# R7FA6T1 register map
Vendor: Renesas; Series: RA6; File version: 1.2
CPU: CM4 r0p1, little endian, MPU, FPU, VTOR, 4 interrupt priority bits
Registers are 8-bit, read-write, reset 0x0 unless marked. A register's access mark holds for its fields unless they carry their own. Offsets are from the block's base; [hi:lo] are bit positions; {n}, {i} and the like mark numbered series; 'fields as' and 'values as' point back to an identical list.

## GPT_OPS — Output Phase Switching Controller
Base 0x40078FF0
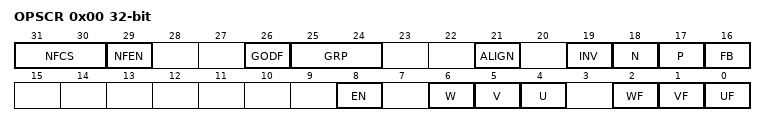
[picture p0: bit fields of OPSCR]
0x00 OPSCR 32-bit — Output Phase Switching Control Register
  [31:30] NFCS — External Input Noise Filter Clock selectionNoise filter sampling clock setting of the external input.
    0=PCLK/1; 1=PCLK/4; 2=PCLK/16; 3=PCLK/64
  [29] NFEN — External Input Noise Filter Enable
    0=Do not use a noise filter to the external input; 1=Use a noise filter to the external input
  [26] GODF — Group output disable function
    0=This bit function is ignored; 1=Group disable will clear OPSCR.EN Bit
  [25:24] GRP — Output disabled source selection
    0=Select Group A output disable source; 1=Select Group B output disable source; 2=Select Group C output disable source; 3=Select Group D output disable source
  [21] ALIGN — Input phase alignment
    0=Input phase is aligned to PCLK; 1=Input phase is aligned PWM
  [19] INV — Invert-Phase Output Control
    0=Positive Logic (Active High)output; 1=Negative Logic (Active Low)output
  [18] N — Negative-Phase Output (N) Control
    0=Level signal output; 1=PWM signal output (PWM of GPT0)
  [17] P — Positive-Phase Output (P) Control
    0=Level signal output; 1=PWM signal output (PWM of GPT0)
  [16] FB — External Feedback Signal EnableThis bit selects the input phase from the software settings and external input.
    0=Select the external input; 1=Select the soft setting(OPSCR.UF, VF, WF)
  [8] EN — Enable-Phase Output Control
    0=Not Output(Hi-Z external terminals); 1=Output
  [6] W ro — Input W-Phase MonitorThis bit monitors the state of the input phase.OPSCR.FB=0:External input monitoring by PCLKOPSCR.FB=1:Software settings (UF/VF/WF)
  [5] V ro — Input V-Phase MonitorThis bit monitors the state of the input phase.OPSCR.FB=0:External input monitoring by PCLKOPSCR.FB=1:Software settings (UF/VF/WF)
  [4] U ro — Input U-Phase MonitorThis bit monitors the state of the input phase.OPSCR.FB=0:External input monitoring by PCLKOPSCR.FB=1:Software settings (UF/VF/WF)
  [2] WF — Input Phase Soft Setting UFThis bit sets the input phase by the software settings.This bit setting is valid when the OPSCR.FB bit = 1.
  [1] VF — Input Phase Soft Setting VFThis bit sets the input phase by the software settings.This bit setting is valid when the OPSCR.FB bit = 1.
  [0] UF — Input Phase Soft Setting WFThis bit sets the input phase by the software settings.This bit setting is valid when the OPSCR.FB bit = 1.

## GPT_ODC — PWM Delay Generation Circuit
Base 0x4007B000
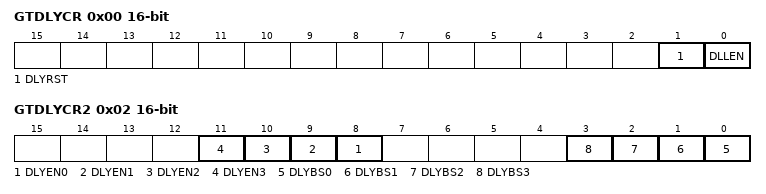
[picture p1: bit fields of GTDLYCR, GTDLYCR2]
0x00 GTDLYCR 16-bit — PWM Output Delay Control Register
  [1] DLYRST — PWM Delay Generation Circuit Reset
    0=Normal operation; 1=Reset
  [0] DLLEN — DLL Operation Enable
    0=Disable DLL operation; 1=Enable DLL operation
0x02 GTDLYCR2 16-bit — PWM Output Delay Control Register2
  [n+8] DLYEN{n} (n=0..3) — PWM Delay Generation Circuit enable for channel {n}
    0=Enable delay generation circuit of channel {n}; 1=Disable delay generation circuit of channel {n}
  [n] DLYBS{n} (n=0..3) — PWM Delay Generation Circuit bypass for channel {n}
    0=Bypass delay generation circuit of channel {n}; 1=Do not bypass delay generation circuit of channel {n}
{0x18+4i} GTDLYR{i}A (i=0..3) 16-bit (alternate view of GTDLYR{i}) — GTIOC{i}A Rising Output Delay Register
  [4:0] DLY — GTIOCnA Output Rising Edge Delay Setting
    0=No delay on rising edges; other=others (Delay of DLY/32 times the PCLKD period is applied.)
{0x1A+4i} GTDLYR{i}B (i=0..3) 16-bit (alternate view of GTDLYR{i}) — GTIOC{i}B Rising Output Delay Register
  [4:0] DLY — GTIOCnB Output Rising Edge Delay Setting
    values as GTDLYR0A.DLY
{0x28+4i} GTDLYF{i}A (i=0..3) 16-bit (alternate view of GTDLYF{i}) — GTIOC{i}A Falling Output Delay Register
  [4:0] DLY — GTIOCnA Output Falling Edge Delay Setting
    values as GTDLYR0A.DLY
{0x2A+4i} GTDLYF{i}B (i=0..3) 16-bit (alternate view of GTDLYF{i}) — GTIOC{i}B Falling Output Delay Register
  [4:0] DLY — GTIOCnB Output Falling Edge Delay Setting
    values as GTDLYR0A.DLY

## KINT — Key Interrupt Function
Base 0x40080000
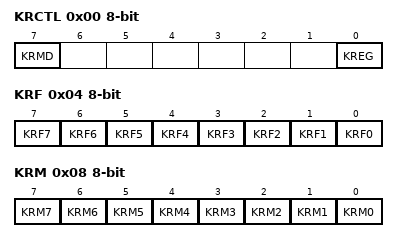
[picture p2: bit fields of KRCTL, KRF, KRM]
0x00 KRCTL — KEY Return Control Register
  [7] KRMD — Usage of Key Interrupt Flags(KR0 to KR7)
    0=Do not use key interrupt flags; 1=Use key interrupt flags
  [0] KREG — Detection Edge Selection (KRF0 to KRF7)
    0=Falling edge; 1=Rising edge
0x04 KRF write-0-clears read-modifies — KEY Return Flag Register
  [all] fields
    0=No interrupt detected; 1=Interrupt detected
  [n] KRF{n} write-0-clears read-modifies (n=0..7) — Key interrupt flag {n}
0x08 KRM — KEY Return Mode Register
  [all] fields
    0=Does not detect key interrupt signal; 1=Detect key interrupt signal
  [n] KRM{n} (n=0..7) — Key interrupt mode control {n}

## ACMPHS0 — High-Speed Analog Comparator 0
Base 0x40085000
Same registers: ACMPHS1 0x40085100, ACMPHS2 0x40085200, ACMPHS3 0x40085300, ACMPHS4 0x40085400, ACMPHS5 0x40085500
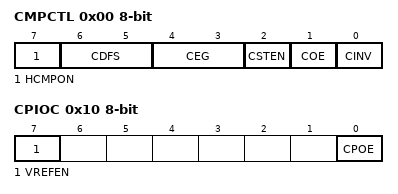
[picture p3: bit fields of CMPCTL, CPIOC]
0x00 CMPCTL — Comparator Control Register
  [7] HCMPON — Comparator operation control
    0=Operation stopped (the comparator outputs a low-level signal); 1=Operation enabled (input to the comparator pins is enabled
  [6:5] CDFS — Noise filter selection
    0=Noise filter not used; 1=Noise filter sampling frequency is 2^3/PCLKB; 2=Noise filter sampling frequency is 2^4/PCLKB; 3=Noise filter sampling frequency is 2^5/PCLKB
  [4:3] CEG — Selection of valid edge (Edge selector)
    0=No edge selection; 1=Rising edge selection; 2=Falling edge selection; 3=Both-edge selection
  [2] CSTEN — Interrupt Select
    0=Output via the Edge selector; 1=Direct output
  [1] COE — Comparator output enable
    0=Comparator output disabled (the output signal is low level); 1=Comparator output enabled
  [0] CINV — Comparator output polarity selection
    0=Comparator output not inverted; 1=Comparator output inverted
0x04 CMPSEL0 — Comparator Input Select Register
  [3:0] CMPSEL — Comparator input selection
    0=No input; 1=IVCMP0 selected; 2=IVCMP1 selected; 4=IVCMP2 selected; 8=IVCMP3 selected; other=others (Setting prohibited)
0x08 CMPSEL1 — Comparator Reference Voltage Select Register
  [3:0] CRVS — Reference voltage selection
    0=No reference voltage; 1=IVREF0 selected; 2=IVREF1 selected; 4=IVREF2 selected; 8=IVREF3 selected; other=others (Setting prohibited)
0x0C CMPMON ro — Comparator Output Monitor Register
  [0] CMPMON — Comparator output monitor
    0=Comparator output Low; 1=Comparator output High
0x10 CPIOC — Comparator Output Control Register
  [7] VREFEN — Internal Vref enable
    0=Internal Vref disable; 1=Internal Vref enable
  [0] CPOE — Comparator output selection
    0=VCOUT pin output of the comparator is disabled (the output signal is low level); 1=VCOUT pin output of the comparator is enabled

## TSD — Temperature Sensor Data
Base 0x407FB17C
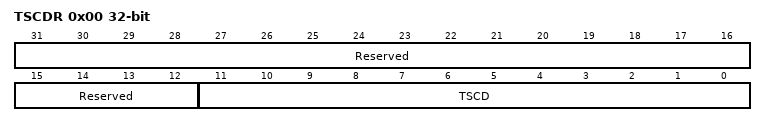
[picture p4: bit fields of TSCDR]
0x00 TSCDR 32-bit ro (reset mask 0xFFFFF000) — Temperature Sensor Calibration Data Register
  [31:12] Reserved — These bits are read as 00000000000000000000.
  [11:0] TSCD — Temperature sensor calibration data is a digital value obtained using the 12-bit A/D converter unit 0 to convert the voltage output by the temperature sensor under the condition Ta = Tj = 127°C and AVCC0 = 3.3 V.
